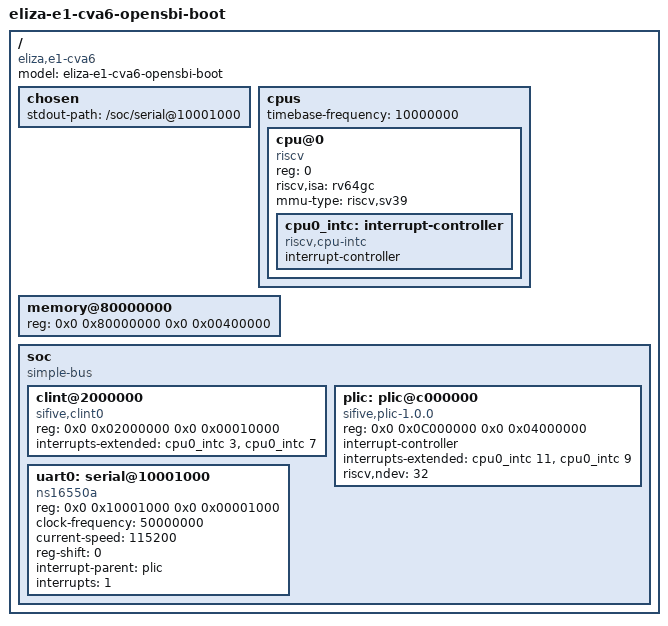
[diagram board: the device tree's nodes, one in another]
/dts-v1/;

/*
 * Device tree for the OpenSBI-on-CVA6 Verilator boot of the E1 SoC.
 *
 * Addresses mirror sw/platform/e1_platform_contract.json (e1_chip_cpu_variant)
 * and sw/platform/generated/e1-platform.dtsi:
 *   CPU   rv64gc, sv39, 1 hart, timebase 10 MHz (CLINT mtime)
 *   CLINT @0x02000000  PLIC @0x0C000000 (32 sources)
 *   UART  ns16550a @0x10001000, reg-shift 0, 50 MHz, 115200, IRQ 1
 *   DRAM  @0x80000000
 *
 * The DRAM node here advertises only the low region the Verilator preload
 * window backs (the contract's full 256 MiB node is correct for silicon; this
 * boot proof exercises the low megabyte the dense preload image occupies).
 * OpenSBI parses this blob from a1 to build its root domain and pick the boot
 * hart; the console UART is registered by the fixed platform glue, not the FDT.
 */

/ {
	#address-cells = <2>;
	#size-cells = <2>;
	compatible = "eliza,e1-cva6";
	model = "eliza-e1-cva6-opensbi-boot";

	chosen {
		stdout-path = "/soc/serial@10001000";
	};

	cpus {
		#address-cells = <1>;
		#size-cells = <0>;
		timebase-frequency = <10000000>;

		cpu@0 {
			device_type = "cpu";
			reg = <0>;
			status = "okay";
			compatible = "riscv";
			riscv,isa = "rv64gc";
			mmu-type = "riscv,sv39";
			cpu0_intc: interrupt-controller {
				#interrupt-cells = <1>;
				interrupt-controller;
				compatible = "riscv,cpu-intc";
			};
		};
	};

	memory@80000000 {
		device_type = "memory";
		reg = <0x0 0x80000000 0x0 0x00400000>;
	};

	soc {
		compatible = "simple-bus";
		#address-cells = <2>;
		#size-cells = <2>;
		ranges;

		clint@2000000 {
			compatible = "sifive,clint0", "riscv,clint0";
			reg = <0x0 0x02000000 0x0 0x00010000>;
			interrupts-extended = <&cpu0_intc 3>, <&cpu0_intc 7>;
		};

		plic: plic@c000000 {
			compatible = "sifive,plic-1.0.0", "riscv,plic0";
			reg = <0x0 0x0C000000 0x0 0x04000000>;
			#interrupt-cells = <1>;
			interrupt-controller;
			interrupts-extended = <&cpu0_intc 11>, <&cpu0_intc 9>;
			riscv,ndev = <32>;
		};

		uart0: serial@10001000 {
			compatible = "ns16550a";
			reg = <0x0 0x10001000 0x0 0x00001000>;
			clock-frequency = <50000000>;
			current-speed = <115200>;
			reg-shift = <0>;
			interrupt-parent = <&plic>;
			interrupts = <1>;
		};
	};
};
